# CY8C5888LTI_LP097 register map
File version: 0.1
Registers are 8-bit, read-write, no defined reset value unless marked. A register's access mark holds for its fields unless they carry their own. Offsets are from the block's base; [hi:lo] are bit positions; 'fields as' and 'values as' point back to an identical list.

## UART
Base 0x00000000
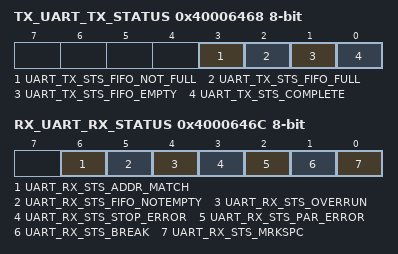
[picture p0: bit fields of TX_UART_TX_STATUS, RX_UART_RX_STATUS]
0x40006468 TX_UART_TX_STATUS — TX status register
  [3] UART_TX_STS_FIFO_NOT_FULL ro, [2] UART_TX_STS_FIFO_FULL ro, [1] UART_TX_STS_FIFO_EMPTY ro, [0] UART_TX_STS_COMPLETE ro
0x4000646C RX_UART_RX_STATUS — RX status register
  [6] UART_RX_STS_ADDR_MATCH ro, [5] UART_RX_STS_FIFO_NOTEMPTY ro, [4] UART_RX_STS_OVERRUN ro, [3] UART_RX_STS_STOP_ERROR ro, [2] UART_RX_STS_PAR_ERROR ro, [1] UART_RX_STS_BREAK ro, [0] UART_RX_STS_MRKSPC ro
0x4000652B RX_UART_RX_ADDRESS1 — RX Address1 Register
0x4000653B RX_UART_RX_ADDRESS2 — RX Address2 Register
0x4000654A TX_UART_TX_DATA — TX Data Register
0x4000654B RX_UART_RX_DATA — RX Data Register

## Timer_ULTRASONIC_R
Base 0x00000000
0x4000640C Timer_ULTRASONIC_R_COUNTER 16-bit — UDB.A0 - Current Down Counter Value
0x4000642C Timer_ULTRASONIC_R_PERIOD 16-bit — UDB.D0 - Assigned Period
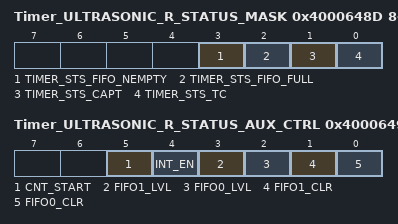
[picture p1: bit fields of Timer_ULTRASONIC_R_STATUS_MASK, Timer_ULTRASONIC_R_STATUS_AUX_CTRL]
0x4000648D Timer_ULTRASONIC_R_STATUS_MASK — UDB Status bits Interrupt Mask Enable Register
  [3] TIMER_STS_FIFO_NEMPTY ro — FIFO Empty status
  [2] TIMER_STS_FIFO_FULL ro — FIFO Full Status
  [1] TIMER_STS_CAPT ro — Enables the Interrupt on Capture
  [0] TIMER_STS_TC ro — Enables the Interrupt on TC
0x4000649D Timer_ULTRASONIC_R_STATUS_AUX_CTRL — UDB Auxilliary Control Register
  [5] CNT_START — FIFO0 clear
    0=E_CNT_START0 (Disable counter); 1=E_CNT_START1 (Enable counter)
  [4] INT_EN
    0=E_INT_EN0 (Interrupt disabled); 1=E_INT_EN1 (Interrupt enabled)
  [3] FIFO1_LVL — FIFO level
    0=E_FIFO_LVL_0 (FIFO LVL: input mode: FIFO not full; output mode: FIFO not empty); 1=E_FIFO_LVL_1 (FIFO LVL: input mode: FIFO at least 1/2 empty; output mode: FIFO at least 1/2 full)
  [2] FIFO0_LVL — FIFO level
    values as FIFO1_LVL
  [1] FIFO1_CLR — FIFO1 clear
    0=E_FIFO_CLR_0 (Normal FIFO operation); 1=E_FIFO_CLR_1 (Clear FIFO state)
  [0] FIFO0_CLR — FIFO0 clear
    values as FIFO1_CLR

## Timer_ULTRASONIC_L
Base 0x00000000
0x40006400 Timer_ULTRASONIC_L_COUNTER 16-bit — UDB.A0 - Current Down Counter Value
0x40006420 Timer_ULTRASONIC_L_PERIOD 16-bit — UDB.D0 - Assigned Period
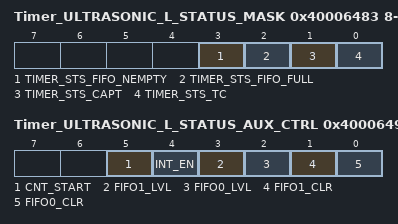
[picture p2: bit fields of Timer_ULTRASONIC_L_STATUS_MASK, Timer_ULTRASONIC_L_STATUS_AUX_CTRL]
0x40006483 Timer_ULTRASONIC_L_STATUS_MASK — UDB Status bits Interrupt Mask Enable Register
  [3] TIMER_STS_FIFO_NEMPTY ro — FIFO Empty status
  [2] TIMER_STS_FIFO_FULL ro — FIFO Full Status
  [1] TIMER_STS_CAPT ro — Enables the Interrupt on Capture
  [0] TIMER_STS_TC ro — Enables the Interrupt on TC
0x40006493 Timer_ULTRASONIC_L_STATUS_AUX_CTRL — UDB Auxilliary Control Register
  [5] CNT_START — FIFO0 clear
    0=E_CNT_START0 (Disable counter); 1=E_CNT_START1 (Enable counter)
  [4] INT_EN
    0=E_INT_EN0 (Interrupt disabled); 1=E_INT_EN1 (Interrupt enabled)
  [3] FIFO1_LVL — FIFO level
    0=E_FIFO_LVL_0 (FIFO LVL: input mode: FIFO not full; output mode: FIFO not empty); 1=E_FIFO_LVL_1 (FIFO LVL: input mode: FIFO at least 1/2 empty; output mode: FIFO at least 1/2 full)
  [2] FIFO0_LVL — FIFO level
    values as FIFO1_LVL
  [1] FIFO1_CLR — FIFO1 clear
    0=E_FIFO_CLR_0 (Normal FIFO operation); 1=E_FIFO_CLR_1 (Clear FIFO state)
  [0] FIFO0_CLR — FIFO0 clear
    values as FIFO1_CLR

## Timer_ULTRASONIC_F
Base 0x00000000
0x40006404 Timer_ULTRASONIC_F_COUNTER 16-bit — UDB.A0 - Current Down Counter Value
0x40006424 Timer_ULTRASONIC_F_PERIOD 16-bit — UDB.D0 - Assigned Period
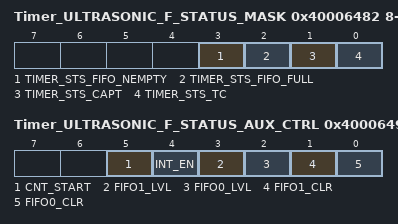
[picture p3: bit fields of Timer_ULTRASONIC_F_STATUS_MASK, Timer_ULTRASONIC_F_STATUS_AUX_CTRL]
0x40006482 Timer_ULTRASONIC_F_STATUS_MASK — UDB Status bits Interrupt Mask Enable Register
  [3] TIMER_STS_FIFO_NEMPTY ro — FIFO Empty status
  [2] TIMER_STS_FIFO_FULL ro — FIFO Full Status
  [1] TIMER_STS_CAPT ro — Enables the Interrupt on Capture
  [0] TIMER_STS_TC ro — Enables the Interrupt on TC
0x40006492 Timer_ULTRASONIC_F_STATUS_AUX_CTRL — UDB Auxilliary Control Register
  [5] CNT_START — FIFO0 clear
    0=E_CNT_START0 (Disable counter); 1=E_CNT_START1 (Enable counter)
  [4] INT_EN
    0=E_INT_EN0 (Interrupt disabled); 1=E_INT_EN1 (Interrupt enabled)
  [3] FIFO1_LVL — FIFO level
    0=E_FIFO_LVL_0 (FIFO LVL: input mode: FIFO not full; output mode: FIFO not empty); 1=E_FIFO_LVL_1 (FIFO LVL: input mode: FIFO at least 1/2 empty; output mode: FIFO at least 1/2 full)
  [2] FIFO0_LVL — FIFO level
    values as FIFO1_LVL
  [1] FIFO1_CLR — FIFO1 clear
    0=E_FIFO_CLR_0 (Normal FIFO operation); 1=E_FIFO_CLR_1 (Clear FIFO state)
  [0] FIFO0_CLR — FIFO0 clear
    values as FIFO1_CLR
